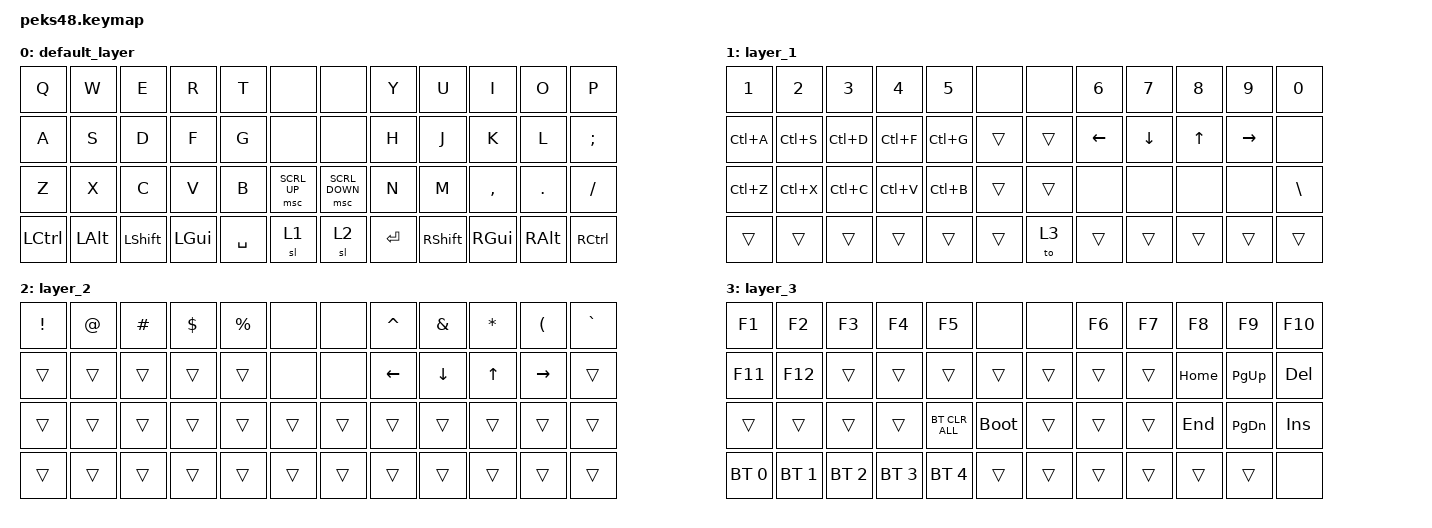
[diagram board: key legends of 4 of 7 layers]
#include <input/processors.dtsi>
#include <dt-bindings/zmk/input_transform.h>
#include <zephyr/dt-bindings/input/input-event-codes.h>
#include <behaviors.dtsi>
#include <dt-bindings/zmk/bt.h>
#include <dt-bindings/zmk/keys.h>
#include <dt-bindings/zmk/pointing.h>

// Conversion definition for using Japanese keyboard with OS settings

#define JP_DQUOTE       AT                // "
#define JP_AMPERSAND    CARET             // &
#define JP_QUOTE        AMPERSAND         // '
#define JP_EQUAL        UNDER             // =
#define JP_CARET        EQUAL             // ^
#define JP_YEN          0x89              // ¥
#define JP_PLUS         COLON             // +
#define JP_TILDE        PLUS              // ~
#define JP_PIPE         LS(0x89)          // |
#define JP_AT           LEFT_BRACKET      // @
#define JP_COLON        SINGLE_QUOTE      // :
#define JP_ASTERISK     DOUBLE_QUOTES     // *
#define JP_BACKQUOTE    LEFT_BRACE        // `
#define JP_UNDERSCORE   LS(0x87)          // _
#define JP_LBRACKET     RIGHT_BRACKET     // [
#define JP_RBRACKET     BACKSLASH         // ]
#define JP_LPAREN       ASTERISK          // (
#define JP_RPAREN       LEFT_PARENTHESIS  // )
#define JP_LBRACE       RIGHT_BRACE       // {
#define JP_RBRACE       PIPE              // }
#define JP_KANA         LANGUAGE_1        // かな
#define JP_EISU         LANGUAGE_2        // 英数
#define JP_HANZEN       GRAVE             // 半角/全角

&mt {
    flavor = "balanced";
    quick-tap-ms = <0>;
};

/ {
    combos {
        compatible = "zmk,combos";

        ctrl {
            bindings = <&sk LCTRL>;
            key-positions = <12 13>;
            layers = <1>;
            timeout-ms = <140>;
        };

        tab {
            bindings = <&kp TAB>;
            key-positions = <0 1>;
            layers = <1>;
        };

        shift {
            bindings = <&sk LEFT_SHIFT>;
            key-positions = <24 25>;
            layers = <1>;
        };

        bs {
            bindings = <&kp BACKSPACE>;
            key-positions = <19 20>;
            layers = <1>;
        };

        lpar {
            bindings = <&kp LEFT_PARENTHESIS>;
            key-positions = <8 9>;
            layers = <1>;
        };

        rpar {
            bindings = <&kp RIGHT_PARENTHESIS>;
            key-positions = <9 10>;
            layers = <1>;
        };

        lblace {
            bindings = <&kp LEFT_BRACKET>;
            key-positions = <20 21>;
            layers = <1>;
        };

        rblace {
            bindings = <&kp RIGHT_BRACKET>;
            key-positions = <21 22>;
            layers = <1>;
        };

        eq {
            bindings = <&kp EQUAL>;
            key-positions = <22 23>;
            layers = <1>;
        };

        minus {
            bindings = <&kp MINUS>;
            key-positions = <10 11>;
            layers = <1>;
        };

        quote {
            bindings = <&kp SINGLE_QUOTE>;
            key-positions = <32 33>;
            layers = <1>;
        };
    };

    keymap {
        compatible = "zmk,keymap";

        default_layer {
            bindings = <
&kp Q      &kp W         &kp E           &kp R         &kp T      &none           &none           &kp Y      &kp U            &kp I          &kp O          &kp P
&kp A      &kp S         &kp D           &kp F         &kp G      &none           &none           &kp H      &kp J            &kp K          &kp L          &kp SEMICOLON
&kp Z      &kp X         &kp C           &kp V         &kp B      &msc SCRL_UP    &msc SCRL_DOWN  &kp N      &kp M            &kp COMMA      &kp DOT        &kp SLASH
&kp LCTRL  &kp LEFT_ALT  &kp LEFT_SHIFT  &kp LEFT_GUI  &kp SPACE  &sl 1           &sl 2           &kp ENTER  &kp RIGHT_SHIFT  &kp RIGHT_GUI  &kp RIGHT_ALT  &kp RCTRL
            >;
        };

        layer_1 {
            bindings = <
&kp NUMBER_1  &kp NUMBER_2  &kp NUMBER_3  &kp NUMBER_4  &kp N5     &none     &none   &kp NUMBER_6    &kp N7          &kp N8        &kp N9     &kp N0
&kp LC(A)     &kp LC(S)     &kp LC(D)     &kp LC(F)     &kp LC(G)  &trans    &trans  &kp LEFT_ARROW  &kp DOWN_ARROW  &kp UP_ARROW  &kp RIGHT  &none
&kp LC(Z)     &kp LC(X)     &kp LC(C)     &kp LC(V)     &kp LC(B)  &trans    &trans  &none           &none           &none         &none      &kp BACKSLASH
&trans        &trans        &trans        &trans        &trans     &trans    &to 3   &trans          &trans          &trans        &trans     &trans
            >;
        };

        layer_2 {
            bindings = <
&kp EXCLAMATION  &kp AT_SIGN  &kp HASH  &kp DOLLAR  &kp PERCENT  &none     &none   &kp CARET       &kp AMPERSAND   &kp ASTERISK  &kp LEFT_PARENTHESIS  &kp GRAVE
&trans           &trans       &trans    &trans      &trans       &none     &none   &kp LEFT_ARROW  &kp DOWN_ARROW  &kp UP_ARROW  &kp RIGHT_ARROW       &trans
&trans           &trans       &trans    &trans      &trans       &trans    &trans  &trans          &trans          &trans        &trans                &trans
&trans           &trans       &trans    &trans      &trans       &trans    &trans  &trans          &trans          &trans        &trans                &trans
            >;
        };

        layer_3 {
            bindings = <
&kp F1        &kp F2        &kp F3        &kp F4        &kp F5          &none          &none   &kp F6  &kp F7  &kp F8    &kp F9         &kp F10
&kp F11       &kp F12       &trans        &trans        &trans          &trans         &trans  &trans  &trans  &kp HOME  &kp PG_UP      &kp DEL
&trans        &trans        &trans        &trans        &bt BT_CLR_ALL  &bootloader    &trans  &trans  &trans  &kp END   &kp PAGE_DOWN  &kp INSERT
&bt BT_SEL 0  &bt BT_SEL 1  &bt BT_SEL 2  &bt BT_SEL 3  &bt BT_SEL 4    &trans         &trans  &trans  &trans  &trans    &trans         &none
            >;
        };

        layer_4 {
            bindings = <
&trans  &trans  &trans  &trans  &trans  &trans    &trans       &bt BT_SEL 0  &bt BT_SEL 1  &bt BT_SEL 2  &bt BT_SEL 3  &bt BT_SEL 4
&trans  &trans  &trans  &trans  &trans  &trans    &trans       &tog 6        &trans        &trans        &trans        &bt BT_CLR
&trans  &trans  &trans  &trans  &trans  &trans    &bootloader  &trans        &trans        &trans        &trans        &bt BT_CLR_ALL
&trans  &trans  &trans  &trans
            >;
        };

        layer_5 {
            bindings = <
&trans  &trans  &trans    &trans    &trans    &trans    &trans  &trans    &trans    &trans    &trans  &trans
&trans  &trans  &mkp MB3  &mkp MB2  &mkp MB1  &trans    &trans  &mkp MB1  &mkp MB2  &mkp MB3  &trans  &trans
&trans  &trans  &trans    &trans    &trans    &trans    &trans  &trans    &trans    &trans    &trans  &trans
&trans  &trans  &trans    &trans
            >;
        };

        layer_6 {
            bindings = <
&trans  &trans  &trans  &trans  &trans  &trans    &trans  &trans  &trans    &trans    &trans    &trans
&trans  &trans  &trans  &trans  &trans  &trans    &trans  &trans  &mkp MB1  &mkp MB3  &mkp MB2  &trans
&trans  &trans  &trans  &trans  &trans  &trans    &trans  &trans  &trans    &trans    &trans    &trans
&trans  &trans  &trans  &trans
            >;
        };
    };
};
